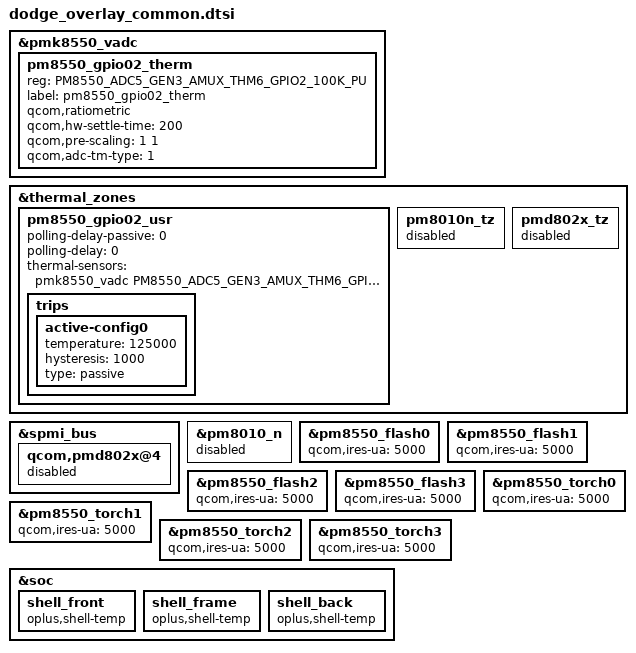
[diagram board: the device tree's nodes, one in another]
&pmk8550_vadc {
	pm8550_gpio02_therm {
		reg = <PM8550_ADC5_GEN3_AMUX_THM6_GPIO2_100K_PU>;
		label = "pm8550_gpio02_therm";
		qcom,ratiometric;
		qcom,hw-settle-time = <200>;
		qcom,pre-scaling = <1 1>;
		qcom,adc-tm-type = <1>;
	};

};

&thermal_zones {
	pm8550_gpio02_usr {
		polling-delay-passive = <0>;
		polling-delay = <0>;
		thermal-sensors = <&pmk8550_vadc PM8550_ADC5_GEN3_AMUX_THM6_GPIO2_100K_PU>;
		trips {
			active-config0 {
				temperature = <125000>;
				hysteresis = <1000>;
				type = "passive";
			};
		};
	};

	pm8010n_tz {
		status = "disabled";
	};

	pmd802x_tz {
		status = "disabled";
	};
};

&spmi_bus {
	qcom,pmd802x@4 {
		status = "disabled";
	};
};

&pm8010_n {
	status = "disabled";
};

&pm8550_flash0 {
	qcom,ires-ua = <5000>;
};

&pm8550_flash1 {
	qcom,ires-ua = <5000>;
};

&pm8550_flash2 {
	qcom,ires-ua = <5000>;
};

&pm8550_flash3 {
	qcom,ires-ua = <5000>;
};

&pm8550_torch0 {
	qcom,ires-ua = <5000>;
};

&pm8550_torch1 {
	qcom,ires-ua = <5000>;
};

&pm8550_torch2 {
	qcom,ires-ua = <5000>;
};

&pm8550_torch3 {
	qcom,ires-ua = <5000>;
};

&soc {
	//#ifdef OPLUS_FEATURE_THERMAL_HORAE
	shell_front {
		compatible = "oplus,shell-temp";
	};

	shell_frame {
		compatible = "oplus,shell-temp";
	};

	shell_back {
		compatible = "oplus,shell-temp";
	};
	//#endif /* OPLUS_FEATURE_THERMAL_HORAE */

};
